# SHAW_0.0 register map
Vendor: Texas Instruments
Peripheral module from a debugger description file (folder mspm33c321x).
Registers are 32-bit, access not given, no defined reset value unless marked. A register's access mark holds for its fields unless they carry their own. Offsets are as the file gives them; lines under a group give offsets from that group; [hi:lo] are bit positions; {n}, {i} and the like mark numbered series; 'fields as' and 'values as' point back to an identical list; <NAME> marks a mode.

## SHAW
0x800 SHAW_GPRCM group
  0x00 SHAW_PWREN rw — Power enable
    [0] ENABLE — Enable the power
      0=DISABLE (Disable Power); 1=ENABLE (Enable Power)
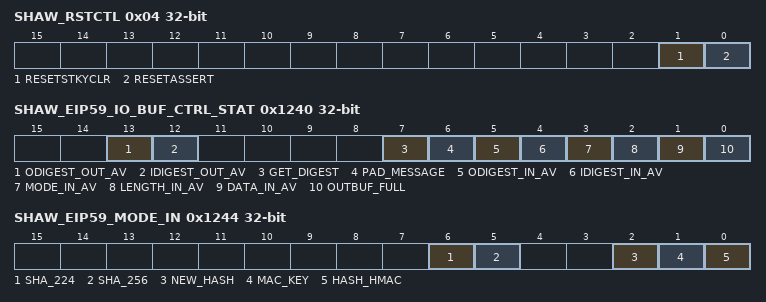
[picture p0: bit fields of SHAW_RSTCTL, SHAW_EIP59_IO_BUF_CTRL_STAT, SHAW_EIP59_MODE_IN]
  0x04 SHAW_RSTCTL rw — Reset Control
    [1] RESETSTKYCLR — Clear the RESETSTKY bit in the STAT register
      0=NOP (Writing 0 has no effect); 1=CLR (Clear reset sticky bit)
    [0] RESETASSERT — Assert reset to the peripheral
      0=NOP (Writing 0 has no effect); 1=ASSERT (Assert reset)
  0x14 SHAW_STAT ro — Status Register
    [16] RESETSTKY — This bit indicates, if the peripheral was reset, since this bit was cleared by RESETSTKYCLR in the RSTCTL register
      0=NORES (The peripheral has not been reset since this bit was last cleared by RESETSTKYCLR in the RSTCTL register); 1=RESET (The peripheral was reset since the last bit clear)
0x1020 SHAW_SHAW_PUB0_IIDX ro — PUB0 IIDX register
  [0] STAT — This register provides the highest priority enabled interrupt index. Value 0x00 means no event pending. Interrupt 1 is the highest priority, IIDX next highest, 4, 8, ... IIDX^31 is the least priority. That is, the least bit position that is set to 1 denotes the highest priority pending interrupt. The priority order is fixed. However, users can implement their own prioritization schemes using other registers that expose the full set of interrupts that have occurred. On each read, only one interrupt is indicated. On a read, the current interrupt (highest priority) is automatically cleared by the hardware and the corresponding interrupt flag in [RIS] and [MIS] are cleared as well. After a read from the CPU (not from the debug interface), the register is updated with the next highest priority interrupt, if none are pending, then it should display 0x0.
0x1028 SHAW_SHAW_PUB0_IMASK rw — PUB0 IMASK register
  [0] OUTPUTRDY — Interrupt Mask. If a bit is set, then corresponding interrupt is un-masked. Un-masking the interrupt causes the raw interrupt to be visible in IIDX, as well as MIS.
0x1030 SHAW_SHAW_PUB0_RIS ro — PUB0 RIS register
  [0] OUTPUTRDY — Raw interrupt status. Reflects all pending interrupts, regardless of masking. The RIS register allows the user to implement a poll scheme. A flag set in this register can be cleared by writing 1 to the ICLR register bit even if the corresponding IMASK bit is not enabled.
0x1038 SHAW_SHAW_PUB0_MIS ro — PUB0 MIS register
  [0] OUTPUTRDY — Masked interrupt status. This is an AND of the IMASK and RIS registers.
0x1040 SHAW_SHAW_PUB0_ISET rw — PUB0 ISET register
  [0] OUTPUTRDY — Interrupt set. Allows interrupts to be set by software (useful in diagnostics and safety checks). Writing a 1 to a bit in ISET will set the event and therefore the related RIS bit also gets set. If the interrupt is enabled through the mask, then the corresponding MIS bit is also set.
0x1048 SHAW_SHAW_PUB0_ICLR rw — PUB0 ICLR register
  [0] OUTPUTRDY — Interrupt clear. Write a 1 to clear corresponding Interrupt.
0x1050 SHAW_SHAW_PUB1_IIDX ro — PUB1 IIDX register
  fields as SHAW_SHAW_PUB0_IIDX
0x1058 SHAW_SHAW_PUB1_IMASK rw — PUB1 IIDX register
  [0] DMA_START_TRIGGER — Interrupt Mask. If a bit is set, then corresponding interrupt is un-masked. Un-masking the interrupt causes the raw interrupt to be visible in IIDX, as well as MIS.
0x1060 SHAW_SHAW_PUB1_RIS ro — PUB1 RIS register
  [0] DMA_START_TRIGGER — Raw interrupt status. Reflects all pending interrupts, regardless of masking. The RIS register allows the user to implement a poll scheme. A flag set in this register can be cleared by writing 1 to the ICLR register bit even if the corresponding IMASK bit is not enabled.
0x1068 SHAW_SHAW_PUB1_MIS ro — PUB1 MIS register
  [0] DMA_START_TRIGGER — Masked interrupt status. This is an AND of the IMASK and RIS registers.
0x1070 SHAW_SHAW_PUB1_ISET rw — PUB1 ISET register
  [0] DMA_START_TRIGGER — Interrupt set. Allows interrupts to be set by software (useful in diagnostics and safety checks). Writing a 1 to a bit in ISET will set the event and therefore the related RIS bit also gets set. If the interrupt is enabled through the mask, then the corresponding MIS bit is also set.
0x1078 SHAW_SHAW_PUB1_ICLR rw — PUB1 ICLR register
  [0] DMA_START_TRIGGER — Interrupt clear. Write a 1 to clear corresponding Interrupt.
0x1080 SHAW_SHAW_DMA_START_TRIGGER rw — DMA Start Trigger Register
  [0] START_TRIGGER — Trigger to start DMA
0x1100 SHAW_SHAW_DATA_FIXED — Fixed Address Wrie Register
{0x1200+4i} SHAW_EIP59_DATA_IN{i}_ (i=0..15) — SHA Data IN {i} register
0x1240 SHAW_EIP59_IO_BUF_CTRL_STAT access per field — SHA Status Register
  [13] ODIGEST_OUT_AV ro — Status to indicate odigest out is available
  [12] IDIGEST_OUT_AV ro — Status to indicate idigest out is available
  [7] GET_DIGEST rw — Write 1 to get the digest on the digest out registers
  [6] PAD_MESSAGE rw — Write 1 to pad the message
  [5] ODIGEST_IN_AV rw — Write 1 to indicate odigest is available
  [4] IDIGEST_IN_AV rw — Write 1 to indicate idigest is available
  [3] MODE_IN_AV rw — Write 1 to indicate mode is available
  [2] LENGTH_IN_AV rw — Write 1 to indicate length is available
  [1] DATA_IN_AV rw — Indicates that the EIP59_DATA_IN_x registers contain a new input data block for processing. #br#The Host must write a 1b to this bit to start an operation on the data in EIP59_DATA_IN_x as soon as the EIP-59 engine is ready to process new input data. #br#Alternatively, when DMA is selected, asserting input signal dma_in_clear to 1b must be used instead to start processing new input data. As an exception, the data_in_av bit must only be used to start processing a zero length message. #br#Writing a '0' to the data_in_av bit has no effect. #br#This bit is automatically cleared (i.e. reads 0b) when the Wide bus EIP-59 engine has copied the EIP59_DATA_IN_x contents. This bit reads as 1b between the time it was set by the Host and the Wide bus EIP-59 engine has started processing the new input block.
  [0] OUTBUF_FULL rw — Indicates output is available, needs to be written 1 to clear this bit before starting new hash
0x1244 SHAW_EIP59_MODE_IN rw — SHA Mode Register
  [6] SHA_224 — Write 1 to compute hash in sha 224 mode, while reading back this information will be available in 4rd bit instead of 6th bit and 6th bit remains reserved
  [5] SHA_256 — Write 1 to compute hash in sha 256 mode, while reading back this information will be available in 3rd bit instead of 5th bit and 5th bit remains reserved
  [2] NEW_HASH — Write 1 to indicate new hash computation
  [1] MAC_KEY — Write 1 to indicate mac key computation
  [0] HASH_HMAC — Write 1 to indicate if it is hmac operation
0x1248 SHAW_EIP59_LENGTH_IN_L — Data Length Register LSB
0x124C SHAW_EIP59_LENGTH_IN_H — Data Length Register MSB
0x1250 SHAW_EIP59_IDIGEST_A — SHA IDIGEST Register
0x1254 SHAW_EIP59_IDIGEST_B — SHA IDIGEST Register
0x1258 SHAW_EIP59_IDIGEST_C — SHA IDIGEST Register
0x125C SHAW_EIP59_IDIGEST_D — SHA IDIGEST Register
0x1260 SHAW_EIP59_IDIGEST_E — SHA IDIGEST Register
0x1264 SHAW_EIP59_IDIGEST_F — SHA IDIGEST Register
0x1268 SHAW_EIP59_IDIGEST_G — SHA IDIGEST Register
0x126C SHAW_EIP59_IDIGEST_H — SHA IDIGEST Register
0x1270 SHAW_EIP59_ODIGEST_A — SHA ODIGEST Register
0x1274 SHAW_EIP59_ODIGEST_B — SHA ODIGEST Register
0x1278 SHAW_EIP59_ODIGEST_C — SHA ODIGEST Register
0x127C SHAW_EIP59_ODIGEST_D — SHA ODIGEST Register
0x1280 SHAW_EIP59_ODIGEST_E — SHA ODIGEST Register
0x1284 SHAW_EIP59_ODIGEST_F — SHA ODIGEST Register
0x1288 SHAW_EIP59_ODIGEST_G — SHA ODIGEST Register
0x128C SHAW_EIP59_ODIGEST_H — SHA ODIGEST Register
0x1290 SHAW_EIP59_DIGEST_A — SHA DIGEST OUT Result Register
0x1294 SHAW_EIP59_DIGEST_B — SHA DIGEST OUT Result Register
0x1298 SHAW_EIP59_DIGEST_C — SHA DIGEST OUT Result Register
0x129C SHAW_EIP59_DIGEST_D — SHA DIGEST OUT Result Register
0x12A0 SHAW_EIP59_DIGEST_E — SHA DIGEST OUT Result Register
0x12A4 SHAW_EIP59_DIGEST_F — SHA DIGEST OUT Result Register
0x12A8 SHAW_EIP59_DIGEST_G — SHA DIGEST OUT Result Register
0x12AC SHAW_EIP59_DIGEST_H — SHA DIGEST OUT Result Register
0x12F8 SHAW_EIP59_CONFIG — SHA Configuration Register
0x12FC SHAW_EIP59_VERSION — SHA Version Register
